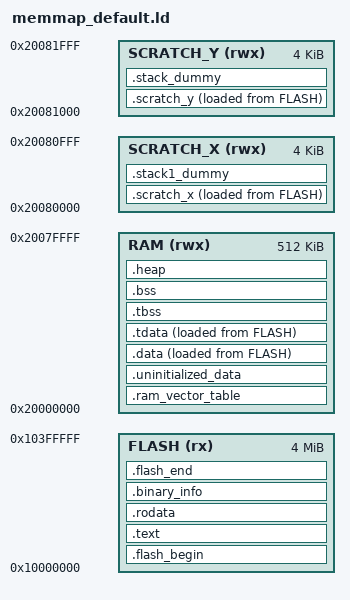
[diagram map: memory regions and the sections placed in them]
MEMORY
{
    FLASH(rx) : ORIGIN = 0x10000000, LENGTH = 4 * 1024 * 1024
    RAM(rwx) : ORIGIN =  0x20000000, LENGTH = 512k
    SCRATCH_X(rwx) : ORIGIN = 0x20080000, LENGTH = 4k
    SCRATCH_Y(rwx) : ORIGIN = 0x20081000, LENGTH = 4k
}

ENTRY(_entry_point)

SECTIONS
{
    .flash_begin : {
        __flash_binary_start = .;
    } > FLASH

    .text : {
        __logical_binary_start = .;
        KEEP (*(.vectors))
        KEEP (*(.binary_info_header))
        __binary_info_header_end = .;
        KEEP (*(.embedded_block))
        __embedded_block_end = .;
        KEEP (*(.reset))

        . = ALIGN(4);
    } > FLASH

    .rodata : {
        *(EXCLUDE_FILE(*libgcc.a: *libc.a:*lib_a-mem*.o *libm.a:) .rodata*)
        *(.srodata*)
        . = ALIGN(4);
        *(SORT_BY_ALIGNMENT(SORT_BY_NAME(.flashdata*)))
        . = ALIGN(4);
    } > FLASH

    /* Machine inspectable binary information */
    . = ALIGN(4);
    __binary_info_start = .;
    .binary_info :
    {
        KEEP(*(.binary_info.keep.*))
        *(.binary_info.*)
    } > FLASH
    __binary_info_end = .;
    . = ALIGN(4);

    .ram_vector_table (NOLOAD): {
        *(.ram_vector_table)
    } > RAM

    .uninitialized_data (NOLOAD): {
        . = ALIGN(4);
        *(.uninitialized_data*)
    } > RAM

    .data : {
        __data_start__ = .;
        *(vtable)

        *(.time_critical*)

        /* remaining .text and .rodata; i.e. stuff we exclude above because we want it in RAM */
        *(.text*)
        . = ALIGN(4);
        *(.rodata*)
        . = ALIGN(4);

        *(.data*)
        *(.sdata*)

        . = ALIGN(4);
        *(.after_data.*)
        . = ALIGN(4);
        /* preinit data */
        PROVIDE_HIDDEN (__mutex_array_start = .);
        KEEP(*(SORT(.mutex_array.*)))
        KEEP(*(.mutex_array))
        PROVIDE_HIDDEN (__mutex_array_end = .);

        *(.jcr)
        . = ALIGN(4);
    } > RAM AT> FLASH

    .tdata : {
        . = ALIGN(4);
		*(.tdata .tdata.* .gnu.linkonce.td.*)
        /* All data end */
        __tdata_end = .;
    } > RAM AT> FLASH
    PROVIDE(__data_end__ = .);

    /* __etext is (for backwards compatibility) the name of the .data init source pointer (...) */
    __etext = LOADADDR(.data);

    .tbss (NOLOAD) : {
        . = ALIGN(4);
        __bss_start__ = .;
        __tls_base = .;
        *(.tbss .tbss.* .gnu.linkonce.tb.*)
        *(.tcommon)

        __tls_end = .;
    } > RAM

    .bss (NOLOAD) : {
        . = ALIGN(4);
        __tbss_end = .;

        *(SORT_BY_ALIGNMENT(SORT_BY_NAME(.bss*)))
        *(COMMON)
        PROVIDE(__global_pointer$ = . + 2K);
        *(.sbss*)
        . = ALIGN(4);
        __bss_end__ = .;
    } > RAM

    .heap (NOLOAD):
    {
        __end__ = .;
        end = __end__;
        KEEP(*(.heap*))
    } > RAM
    /* historically on GCC sbrk was growing past __HeapLimit to __StackLimit, however
       to be more compatible, we now set __HeapLimit explicitly to where the end of the heap is */
    __HeapLimit = ORIGIN(RAM) + LENGTH(RAM);

    /* Start and end symbols must be word-aligned */
    .scratch_x : {
        __scratch_x_start__ = .;
        *(.scratch_x.*)
        . = ALIGN(4);
        __scratch_x_end__ = .;
    } > SCRATCH_X AT > FLASH
    __scratch_x_source__ = LOADADDR(.scratch_x);

    .scratch_y : {
        __scratch_y_start__ = .;
        *(.scratch_y.*)
        . = ALIGN(4);
        __scratch_y_end__ = .;
    } > SCRATCH_Y AT > FLASH
    __scratch_y_source__ = LOADADDR(.scratch_y);

    .stack1_dummy (NOLOAD):
    {
        *(.stack1*)
    } > SCRATCH_X
    .stack_dummy (NOLOAD):
    {
        KEEP(*(.stack*))
    } > SCRATCH_Y

    .flash_end : {
        KEEP(*(.embedded_end_block*))
        PROVIDE(__flash_binary_end = .);
    } > FLASH =0xaa

    /* stack limit is poorly named, but historically is maximum heap ptr */
    __StackLimit = ORIGIN(RAM) + LENGTH(RAM);
    __StackOneTop = ORIGIN(SCRATCH_X) + LENGTH(SCRATCH_X);
    __StackTop = ORIGIN(SCRATCH_Y) + LENGTH(SCRATCH_Y);
    __StackOneBottom = __StackOneTop - SIZEOF(.stack1_dummy);
    __StackBottom = __StackTop - SIZEOF(.stack_dummy);
    PROVIDE(__stack = __StackTop);

    /* picolibc and LLVM */
    PROVIDE (__heap_start = __end__);
    PROVIDE (__heap_end = __HeapLimit);
    PROVIDE( __tls_align = MAX(ALIGNOF(.tdata), ALIGNOF(.tbss)) );
    PROVIDE( __tls_size_align = (__tls_size + __tls_align - 1) & ~(__tls_align - 1));
    PROVIDE( __arm32_tls_tcb_offset = MAX(8, __tls_align) );

    /* llvm-libc */
    PROVIDE (_end = __end__);
    PROVIDE (__llvm_libc_heap_limit = __HeapLimit);

    /* Check if data + heap + stack exceeds RAM limit */
    ASSERT(__StackLimit >= __HeapLimit, "region RAM overflowed")

    ASSERT( __binary_info_header_end - __logical_binary_start <= 1024, "Binary info must be in first 1024 bytes of the binary")
    ASSERT( __embedded_block_end - __logical_binary_start <= 4096, "Embedded block must be in first 4096 bytes of the binary")
}

